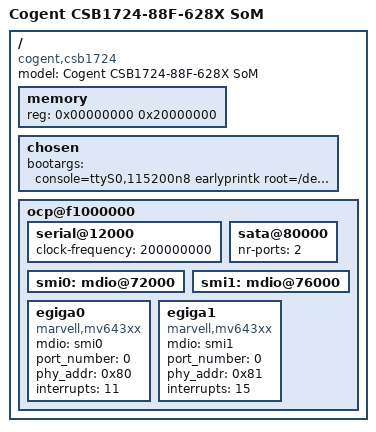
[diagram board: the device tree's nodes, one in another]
/dts-v1/;

/include/ "kirkwood.dtsi"

/ {
	model = "Cogent CSB1724-88F-628X SoM";
	compatible = "cogent,csb1724", "marvell,kirkwood-88f6281", "marvell,kirkwood";

	memory {
		device_type = "memory";
		reg = <0x00000000 0x20000000>;
	};

	chosen {
		bootargs = "console=ttyS0,115200n8 earlyprintk root=/dev/sda3";
	};

	ocp@f1000000 {
		serial@12000 {
			clock-frequency = <200000000>;
			status = "ok";
		};

		sata@80000 {
			nr-ports = <2>;
			status = "ok";
		};

		smi0: mdio@72000 {
			status = "ok";
		};

		smi1: mdio@76000 {
			status = "ok";
		};

		egiga0 {
			compatible = "marvell,mv643xx";
			mdio = <&smi0>;
			port_number = <0>;
			phy_addr = <0x80>;
			interrupts = <11>;
		};

		egiga1 {
			compatible = "marvell,mv643xx";
			mdio = <&smi1>;
			port_number = <0>;
			phy_addr = <0x81>;
			interrupts = <15>;
		};

	};

};
